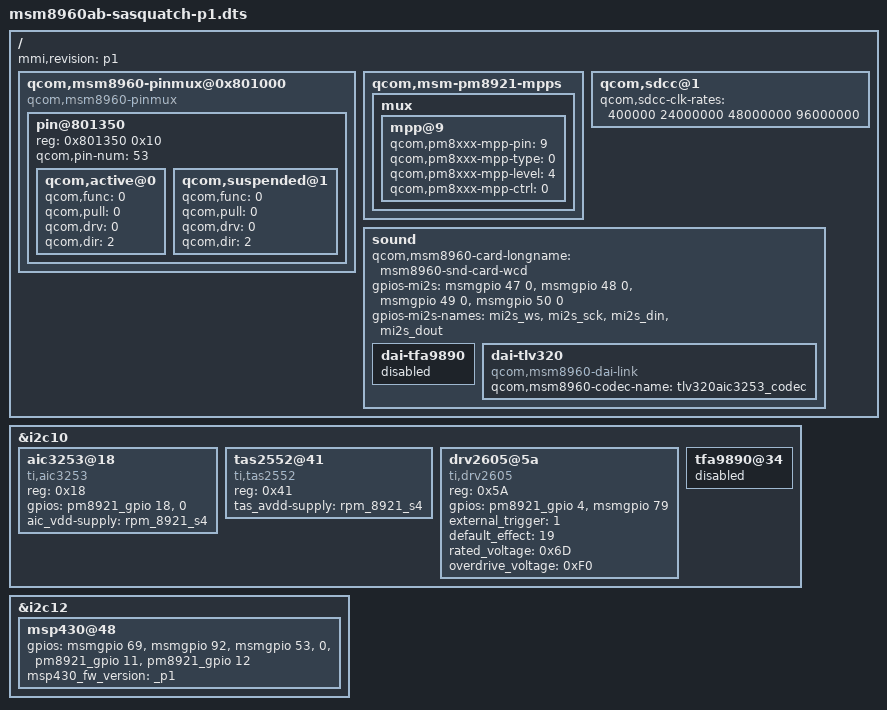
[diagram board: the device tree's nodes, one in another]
/dts-v1/;

/include/ "msm8960ab-sasquatch-common.dtsi"

/include/ "msm8960ab-sasquatch-p1-legacy.dtsi"

/ {
	mmi,revision = "p1";

	qcom,msm8960-pinmux@0x801000 {
		compatible = "qcom,msm8960-pinmux";
		#address-cells = <1>;
		#size-cells = <1>;

		pin@801350 {  /* AP_TO_SP_FLASH_EN                          */
			reg = <0x801350 0x10>;
			qcom,pin-num = <53>;
			qcom,active@0 {
				qcom,func = <0>;  /* gpio_in_out(53)        */
				qcom,pull = <0>;  /* none                   */
				qcom,drv = <0>;   /* 2ma                    */
				qcom,dir = <2>;   /* out_low                */
			};
			qcom,suspended@1 {
				qcom,func = <0>;  /* gpio_in_out(53)        */
				qcom,pull = <0>;  /* none                   */
				qcom,drv = <0>;   /* 2ma                    */
				qcom,dir = <2>;   /* out_low                */
			};
		};
	};

	/* PM8921 - MPP */
	qcom,msm-pm8921-mpps {
		mux {
			mpp@9 {
				/* EMU_DMB_PPD_DET_N */
				qcom,pm8xxx-mpp-pin = <9>;

				/*
				 * type   : D_INPUT
				 * level  : L17
				 * ctrl   : DIN_TO_INT
				 */
				qcom,pm8xxx-mpp-type = <0>;
				qcom,pm8xxx-mpp-level = <4>;
				qcom,pm8xxx-mpp-ctrl = <0>;
			};
		};
	};

	/* eMMC - P1 layout can only do HS200 at 96MHz */
	qcom,sdcc@1 {
		qcom,sdcc-clk-rates = <400000 24000000 48000000 96000000>;
	};

	sound {
		/* P1 aren't properly connected; use wcd only */
		qcom,msm8960-card-longname = "msm8960-snd-card-wcd";

		/* P1 does not have MCLK for MI2S */
		gpios-mi2s = <&msmgpio 47 0>, /* WS   */
			     <&msmgpio 48 0>, /* SCK  */
			     <&msmgpio 49 0>, /* DIN  */
			     <&msmgpio 50 0>; /* DOUT */
		gpios-mi2s-names = "mi2s_ws",
				  "mi2s_sck",
				  "mi2s_din",
				  "mi2s_dout";


		dai-tfa9890 {
			status = "disabled";
		};

		dai-tlv320 {
			compatible = "qcom,msm8960-dai-link";
			qcom,msm8960-codec-name = "tlv320aic3253_codec";
		};
	};
};

/* GSBI10 - I2C */
&i2c10 {
	/* TI tlv320aic3253 */
	aic3253@18 {
		compatible = "ti,aic3253";
		reg = <0x18>;
		gpios = <&pm8921_gpio 18 0>, /* RESET */
			<0>; 		     /* MCLK  */
		aic_vdd-supply = <&rpm_8921_s4>;
	};

	tas2552@41 {
		compatible = "ti,tas2552";
		reg = <0x41>;
		tas_avdd-supply = <&rpm_8921_s4>;
	};

	/* TI drv2605 */
	drv2605@5a {
		compatible = "ti,drv2605";
		reg = <0x5A>;
		gpios = <&pm8921_gpio 4 0>, /* EN_GPIO */
			<&msmgpio 79 0>;    /* Trigger */

		external_trigger = <1>;
		default_effect = <19>;      /* Strong Click 3 60% */
		rated_voltage = <0x6D>;
		overdrive_voltage = <0xF0>;
	};

	tfa9890@34 {
		status = "disabled";
	};
};

/* GSBI12 - I2C */
&i2c12 {
	msp430@48 {
		gpios = <&msmgpio 69 0>,     /* IRQ */
			<&msmgpio 92 0>,     /* RESET */
			<&msmgpio 53 0>,     /* BSLEN */
			<0>,                 /* WakeIRQ */
			<&pm8921_gpio 11 0>, /* MIPI_REQ */
			<&pm8921_gpio 12 0>; /* MIPI_BUSY */
			msp430_fw_version = "_p1";
        };
};
